# STM32F215 register map
File version: 1.1
CPU: CM3 r1p1, little endian, no MPU, no FPU, 4 interrupt priority bits
Registers are 32-bit, read-write, reset 0x0 unless marked. A register's access mark holds for its fields unless they carry their own. Offsets are from the block's base; [hi:lo] are bit positions; lines under a group give offsets from that group; {n}, {i} and the like mark numbered series.

## OTG_FS_PWRCLK — USB on the go full speed
Base 0x50000E00
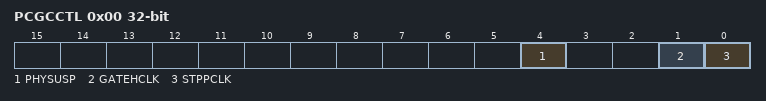
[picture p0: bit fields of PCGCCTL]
0x00 PCGCCTL — OTG_FS power and clock gating control register (OTG_FS_PCGCCTL)
  [4] PHYSUSP — PHY Suspended
  [1] GATEHCLK
  [0] STPPCLK — Stop PHY clock

## EXTI — External interrupt/event controller
Base 0x40013C00
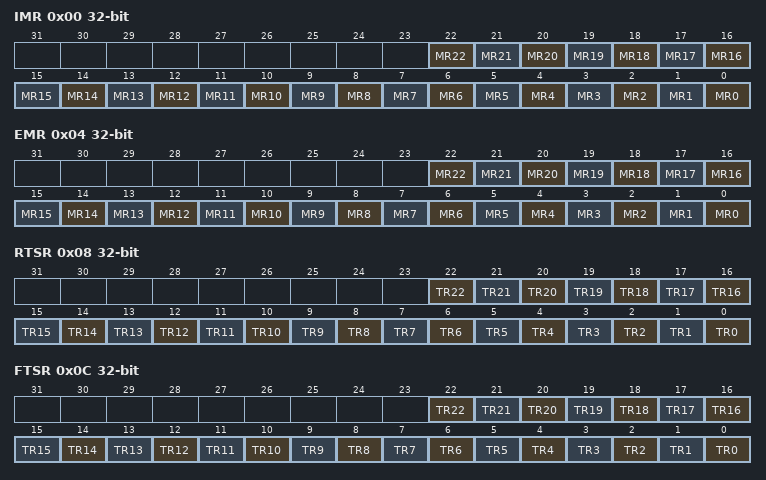
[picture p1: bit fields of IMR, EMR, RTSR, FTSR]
0x00 IMR — Interrupt mask register (EXTI_IMR)
  [n] MR{n} (n=0..22) — Interrupt Mask on line {n}
    0=Masked (Interrupt request line is masked); 1=Unmasked (Interrupt request line is unmasked)
0x04 EMR — Event mask register (EXTI_EMR)
  [n] MR{n} (n=0..22) — Event Mask on line {n}
    0=Masked (Event request line is masked); 1=Unmasked (Event request line is unmasked)
0x08 RTSR — Rising Trigger selection register (EXTI_RTSR)
  [n] TR{n} (n=0..22) — Rising trigger event configuration of line {n}
    0=Disabled (Rising edge trigger is disabled); 1=Enabled (Rising edge trigger is enabled)
0x0C FTSR — Falling Trigger selection register (EXTI_FTSR)
  [n] TR{n} (n=0..22) — Falling trigger event configuration of line {n}
    0=Disabled (Falling edge trigger is disabled); 1=Enabled (Falling edge trigger is enabled)
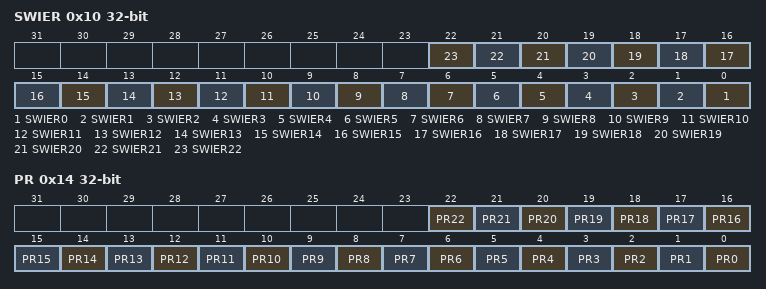
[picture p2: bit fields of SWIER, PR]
0x10 SWIER — Software interrupt event register (EXTI_SWIER)
  [n] SWIER{n} (n=0..22) — Software Interrupt on line {n}
    on write: 1=Pend (Generates an interrupt request)
0x14 PR — Pending register (EXTI_PR)
  [n] PR{n} (n=0..22) write-1-clears — Pending bit {n}
    on read: 0=NotPending (No trigger request occurred); 1=Pending (Selected trigger request occurred) | on write: 1=Clears pending bit

## HASH — Hash processor
Base 0x50060400
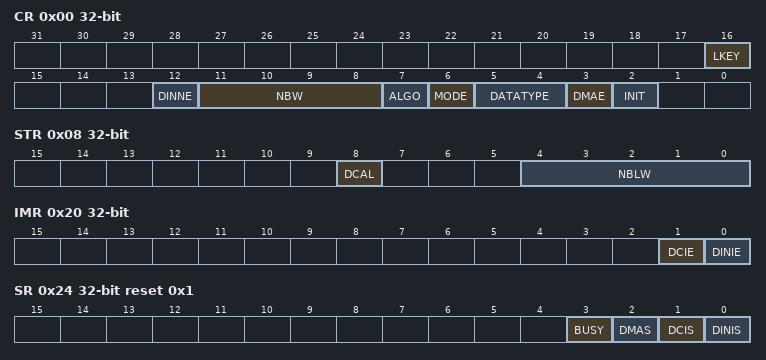
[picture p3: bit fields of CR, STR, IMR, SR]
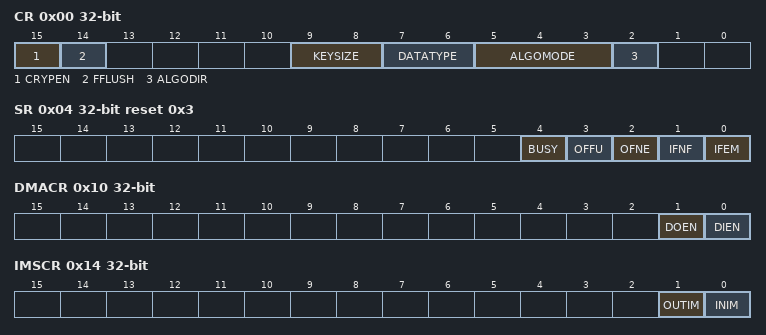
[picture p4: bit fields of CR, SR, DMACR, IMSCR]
0x00 CR access per field — control register
  [16] LKEY rw — Long key selection
  [12] DINNE ro — DIN not empty
  [11:8] NBW ro — Number of words already pushed
  [7] ALGO rw — Algorithm selection
  [6] MODE rw — Mode selection
  [5:4] DATATYPE rw — Data type selection
  [3] DMAE rw — DMA enable
  [2] INIT wo — Initialize message digest calculation
0x04 DIN — data input register
  [31:0] DATAIN — Data input
0x08 STR wo — start register
  [8] DCAL — Digest calculation
  [4:0] NBLW — Number of valid bits in the last word of the message
{0xC+4i} HR{i} (i=0..4) ro — digest registers
  [31:0] H — H0
0x20 IMR — interrupt enable register
  [1] DCIE — Digest calculation completion interrupt enable
  [0] DINIE — Data input interrupt enable
0x24 SR access per field reset 0x1 — status register
  [3] BUSY ro — Busy bit
  [2] DMAS ro — DMA Status
  [1] DCIS rw — Digest calculation completion interrupt status
  [0] DINIS rw — Data input interrupt status
{0xF8+4i} CSR{i} (i=0..50) — context swap registers
  [31:0] CSR — CSR0

## CRYP — Cryptographic processor
Base 0x50060000
0x00 CR access per field — control register
  [15] CRYPEN rw — Cryptographic processor enable
  [14] FFLUSH wo — FIFO flush
  [9:8] KEYSIZE rw — Key size selection (AES mode only)
  [7:6] DATATYPE rw — Data type selection
  [5:3] ALGOMODE rw — Algorithm mode
  [2] ALGODIR rw — Algorithm direction
0x04 SR ro reset 0x3 — status register
  [4] BUSY — Busy bit
  [3] OFFU — Output FIFO full
  [2] OFNE — Output FIFO not empty
  [1] IFNF — Input FIFO not full
  [0] IFEM — Input FIFO empty
0x08 DIN — data input register
  [31:0] DATAIN — Data input
0x0C DOUT ro — data output register
  [31:0] DATAOUT — Data output
0x10 DMACR — DMA control register
  [1] DOEN — DMA output enable
  [0] DIEN — DMA input enable
0x14 IMSCR — interrupt mask set/clear register
  [1] OUTIM — Output FIFO service interrupt mask
  [0] INIM — Input FIFO service interrupt mask
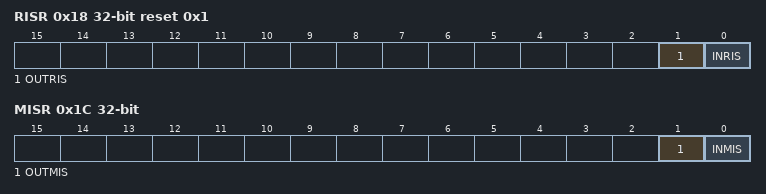
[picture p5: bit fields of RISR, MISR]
0x18 RISR ro reset 0x1 — raw interrupt status register
  [1] OUTRIS — Output FIFO service raw interrupt status
  [0] INRIS — Input FIFO service raw interrupt status
0x1C MISR ro — masked interrupt status register
  [1] OUTMIS — Output FIFO service masked interrupt status
  [0] INMIS — Input FIFO service masked interrupt status
{0x20+8i} KEY{i} (i=0..3) group — Cluster KEY{i}, containing K?LR, K?RR
  0x00 KLR wo — key registers
    [31:0] b2 — b224
  0x04 KRR wo — key registers
    [31:0] b — b192
{0x40+8i} INIT{i} (i=0..1) group — Cluster INIT{i}, containing IV?LR, IV?RR
  0x00 IVLR — initialization vector registers
    [31:0] IV — IV31
  0x04 IVRR — initialization vector registers
    [31:0] IV — IV63
